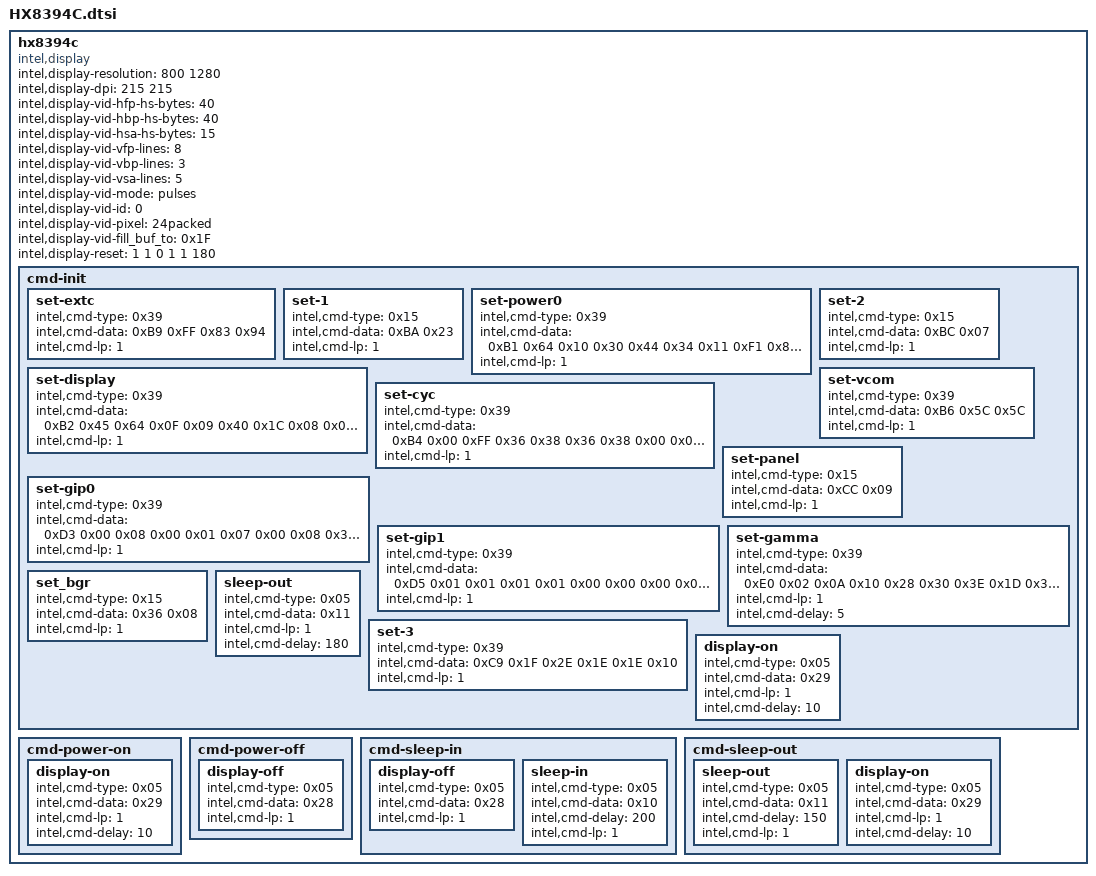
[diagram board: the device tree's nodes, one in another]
	hx8394c {
		compatible = "intel,display";
		intel,display-resolution= <800 1280>;
		intel,display-dpi= <215 215>;

		/* MIPI-DSI video mode settings */
		intel,display-vid-hfp-hs-bytes = <40>;
		intel,display-vid-hbp-hs-bytes = <40>;
		intel,display-vid-hsa-hs-bytes = <15>;
		intel,display-vid-vfp-lines = <8>;
		intel,display-vid-vbp-lines = <3>;
		intel,display-vid-vsa-lines = <5>;

		intel,display-vid-mode = "pulses";
		intel,display-vid-id = <0>;
		intel,display-vid-pixel = "24packed";
		intel,display-vid-fill_buf_to = <0x1F>;

		intel,display-reset = <1 1 0 1 1 180>;

		cmd-init {
			set-extc {
				intel,cmd-type = <0x39>;
				intel,cmd-data = <0xB9 0xFF 0x83 0x94>;
				intel,cmd-lp = <1>;
			};
			set-1 {
				intel,cmd-type = <0x15>;
				intel,cmd-data = <0xBA 0x23>;
				intel,cmd-lp = <1>;
			};
			set-power0 {
				intel,cmd-type = <0x39>;
				intel,cmd-data = <0xB1 0x64 0x10 0x30 0x44 0x34 0x11 0xF1 0x81 0x70 0xD9 0x34 0x80 0xC0 0xD2 0x1F>;
				intel,cmd-lp = <1>;
			};
			set-2 {
				intel,cmd-type = <0x15>;
				intel,cmd-data = <0xBC 0x07>;
				intel,cmd-lp = <1>;
			};
			set-display {
				intel,cmd-type = <0x39>;
				intel,cmd-data = <0xB2 0x45 0x64 0x0F 0x09 0x40 0x1C 0x08 0x08 0x1C 0x4D 0x00 0x00>;
				intel,cmd-lp = <1>;
			};
			set-cyc {
				intel,cmd-type = <0x39>;
				intel,cmd-data = <0xB4 0x00 0xFF 0x36 0x38 0x36 0x38 0x00 0x00 0x01 0x68 0x04 0x68 0x18 0x60 0x18 0x60 0x00 0x00 0x01 0x30 0x0F 0x68>;
				intel,cmd-lp = <1>;
			};
			set-vcom {
				intel,cmd-type = <0x39>;
				intel,cmd-data = <0xB6 0x5C 0x5C>;
				intel,cmd-lp = <1>;
			};
			set-panel {
				intel,cmd-type = <0x15>;
				intel,cmd-data = <0xCC 0x09>;
				intel,cmd-lp = <1>;
			};
			set-gip0 {
				intel,cmd-type = <0x39>;
				intel,cmd-data = <0xD3 0x00 0x08 0x00 0x01 0x07 0x00 0x08 0x32 0x10 0x0A 0x00 0x05 0x00 0x20 0x0A 0x05 0x09 0x00 0x32 0x10 0x08 0x00 0x11 0x11 0x0D 0x07 0x23 0x0D 0x07 0x47 0x0D 0x08>;
				intel,cmd-lp = <1>;
			};
			set-gip1 {
				intel,cmd-type = <0x39>;
				intel,cmd-data = <0xD5 0x01 0x01 0x01 0x01 0x00 0x00 0x00 0x00 0x03 0x03 0x03 0x03 0x02 0x02 0x02 0x02 0x20 0x20 0x18 0x18 0x18 0x18 0x18 0x18 0x18 0x18 0x18 0x18 0x18 0x18 0x21 0x21 0x18 0x18 0x18 0x18 0x18 0x18 0x18 0x18 0x18 0x18 0x18 0x18>;
				intel,cmd-lp = <1>;
			};
			set-gamma {
				intel,cmd-type = <0x39>;
				intel,cmd-data = <0xE0 0x02 0x0A 0x10 0x28 0x30 0x3E 0x1D 0x3A 0x05 0x0B 0x0D 0x17 0x0E 0x12 0x15 0x12 0x13 0x06 0x12 0x14 0x18 0x02 0x0A 0x10 0x28 0x30 0x3E 0x1D 0x3A 0x05 0x0B 0x0D 0x17 0x0E 0x12 0x15 0x12 0x13 0x06 0x12 0x14 0x18>;
				intel,cmd-lp = <1>;
				intel,cmd-delay = <5>;
			};
			/*
			set-cabc-1 {
				intel,cmd-type = <0x15>;
				intel,cmd-data = <0x51 0xFF>;
				intel,cmd-lp = <1>;
			};
			set-cabc-2 {
				intel,cmd-type = <0x15>;
				intel,cmd-data = <0x53 0x24>;
				intel,cmd-lp = <1>;
			};
			set-cabc-3 {
				intel,cmd-type = <0x15>;
				intel,cmd-data = <0x55 0x01>;
				intel,cmd-lp = <1>;
				intel,cmd-delay = <5>;
			};
			*/
			set_bgr {
				intel,cmd-type = <0x15>;
				intel,cmd-data = <0x36 0x08>;
				intel,cmd-lp = <1>;
			};
			sleep-out {
				intel,cmd-type = <0x05>;
				intel,cmd-data = <0x11>;
				intel,cmd-lp = <1>;
				intel,cmd-delay = <180>;
			};
			set-3 {
				intel,cmd-type = <0x39>;
				intel,cmd-data = <0xC9 0x1F 0x2E 0x1E 0x1E 0x10>;
				intel,cmd-lp = <1>;
			};
			display-on {
				intel,cmd-type = <0x05>;
				intel,cmd-data = <0x29>;
				intel,cmd-lp = <1>;
				intel,cmd-delay = <10>;
			};
		};

		cmd-power-on {
			display-on {
				intel,cmd-type = <0x05>;
				intel,cmd-data = <0x29>;
				intel,cmd-lp = <1>;
				intel,cmd-delay = <10>;
			};
		};

		cmd-power-off {
			display-off {
				intel,cmd-type = <0x05>;
				intel,cmd-data = <0x28>;
				intel,cmd-lp = <1>;
			};
		};

		cmd-sleep-in {
			display-off {
				intel,cmd-type = <0x05>;
				intel,cmd-data = <0x28>;
				intel,cmd-lp = <1>;
			};
			sleep-in {
				intel,cmd-type = <0x05>;
				intel,cmd-data = <0x10>;
				intel,cmd-delay = <200>;
				intel,cmd-lp = <1>;
			};
		};

		cmd-sleep-out {
			sleep-out {
				intel,cmd-type = <0x05>;
				intel,cmd-data = <0x11>;
				intel,cmd-delay = <150>;
				intel,cmd-lp = <1>;
			};
			display-on {
				intel,cmd-type = <0x05>;
				intel,cmd-data = <0x29>;
				intel,cmd-lp = <1>;
				intel,cmd-delay = <10>;
			};
		};

	};
